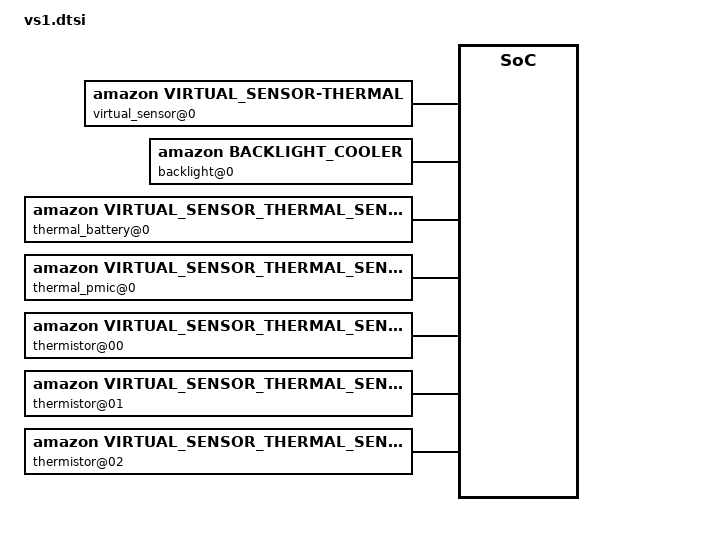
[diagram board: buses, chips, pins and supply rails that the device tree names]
/*
 * Copyright (c) 2017 MediaTek Inc.
 * Author: Keene Tsai <keene.tsai@mediatek.com>
 *
 * This program is free software; you can redistribute it and/or modify
 * it under the terms of the GNU General Public License version 2 as
 * published by the Free Software Foundation.
 *
 * This program is distributed in the hope that it will be useful,
 * MERCHANTABILITY or FITNESS FOR A PARTICULAR PURPOSE.  See the
 * GNU General Public License for more details.
 */
vs1_wire: vs1_wire {
	compatible = "amazon,vs1_wire", "simple-bus";
	status = "okay";

	/*
	 * Virtual sensor
	 * select_device: Decide to register which thermal_zone device
	 * 0: register to thermal_zone9, 1: register to thermal_zone10
	 */
	virtual_sensor@0{
		compatible = "amazon,virtual_sensor-thermal";
		dev_id = <0>;
		num_trips = <9>;
		mode = <0>;
		polling_delay = <3000>;
		governor_name = "virtual_sensor";
		num_tbps = <3>;
		temp = <44000 44500 45000 45500 49000 51000 53000 54000 56000 56000 56000 56000>;
		type = <0 0 0 0 0 0 0 0 3 3 3 3>;
		hyst = <3000 0 0 0 0 0 0 3000 0 0 0 0>;
		num_cdevs = <2>;
		cdev_names = "thermal_budget0","lcd-backlight0";
	};
	/* Backlight Cooler */
	backlight@0 {
		compatible = "amazon,backlight_cooler";
		type = "lcd-backlight0";
		state = <0>;
		max_state = <12>;
		level = <255>;
		thermal_cooler_id = <1>;
		levels = <255 255 255 220 200 175 175 175 175 175 175 175>;
	};

	/* Thermal_budget Cooler */
	thermal_budget@0 {
		compatible = "amazon,thermal_budget_cooler";
		type = "thermal_budget0";
		state = <0>;
		max_state = <12>;
		level = <4600>;
		thermal_cooler_id = <2>;
		levels = <941 846 707 625 553 441 372 235 235 235 235 235>;
	};
	/*Virtual sensor battery*/
	thermal_battery@0{
		compatible = "amazon,virtual_sensor_thermal_sensor";
		thermal_sensor,offset = <5040>;
		thermal_sensor,offset_invert = <0>;
		thermal_sensor,alpha = <726>;
		thermal_sensor,weight = <228>;
		thermal_sensor,weight_invert = <0>;
		thermal_sensor_id = <1>;
		aux_channel_num = <0>;
		select_device = <0>;
	};
	/*Virtual sensor pmic*/
	thermal_pmic@0{
		compatible = "amazon,virtual_sensor_thermal_sensor";
		thermal_sensor,offset = <50200>;
		thermal_sensor,alpha = <417>;
		thermal_sensor,weight = <0>;
		thermal_sensor,weight_invert = <0>;
		thermal_sensor,offset_invert = <0>;
		thermal_sensor_id = <3>;
		aux_channel_num = <0>;
		select_device = <0>;
	};
	/* Virtual sensor thermistor */
	thermistor@00 {
		compatible = "amazon,virtual_sensor_thermal_sensor";
		thermal_sensor,offset = <12600>;
		thermal_sensor,offset_invert = <1>;
		thermal_sensor,alpha = <1>;
		thermal_sensor,weight = <240>;
		thermal_sensor,weight_invert = <0>;
		thermal_sensor_id = <5>;
		aux_channel_num = <0>;
		select_device = <0>;
	};
	thermistor@01 {
		compatible = "amazon,virtual_sensor_thermal_sensor";
		thermal_sensor,offset = <18300>;
		thermal_sensor,offset_invert = <0>;
		thermal_sensor,alpha = <330>;
		thermal_sensor,weight = <160>;
		thermal_sensor,weight_invert = <0>;
		thermal_sensor_id = <5>;
		aux_channel_num = <1>;
		select_device = <0>;
	};
	thermistor@02 {
		compatible = "amazon,virtual_sensor_thermal_sensor";
		thermal_sensor,offset = <16600>;
		thermal_sensor,offset_invert = <1>;
		thermal_sensor,alpha = <232>;
		thermal_sensor,weight = <257>;
		thermal_sensor,weight_invert = <0>;
		thermal_sensor_id = <5>;
		aux_channel_num = <2>;
		select_device = <0>;
	};
};
vs1_wpc: vs1_wpc {
	compatible = "amazon,vs1_wpc", "simple-bus";
	status = "disabled";

	/*
	 * Virtual sensor
	 * select_device: Decide to register which thermal_zone device
	 * 0: register to thermal_zone9, 1: register to thermal_zone10
	 */
	virtual_sensor@0{
		compatible = "amazon,virtual_sensor-thermal";
		dev_id = <0>;
		num_trips = <9>;
		mode = <0>;
		polling_delay = <3000>;
		governor_name = "virtual_sensor";
		num_tbps = <3>;
		temp = <44000 44500 45000 45500 49000 51000 53000 54000 56000 56000 56000 56000>;
		type = <0 0 0 0 0 0 0 0 3 3 3 3>;
		hyst = <3000 0 0 0 0 0 0 3000 0 0 0 0>;
		num_cdevs = <2>;
		cdev_names = "thermal_budget0","lcd-backlight0";
	};
	/* Backlight Cooler */
	backlight@0 {
		compatible = "amazon,backlight_cooler";
		type = "lcd-backlight0";
		state = <0>;
		max_state = <12>;
		level = <255>;
		thermal_cooler_id = <1>;
		levels = <255 255 255 220 200 175 175 175 175 175 175 175>;
	};

	/* Thermal_budget Cooler */
	thermal_budget@0 {
		compatible = "amazon,thermal_budget_cooler";
		type = "thermal_budget0";
		state = <0>;
		max_state = <12>;
		level = <4600>;
		thermal_cooler_id = <2>;
		levels = <941 846 707 625 553 441 372 235 235 235 235 235>;
	};
	/*Virtual sensor battery*/
	thermal_battery@0{
		compatible = "amazon,virtual_sensor_thermal_sensor";
		thermal_sensor,offset = <29700>;
		thermal_sensor,offset_invert = <0>;
		thermal_sensor,alpha = <1000>;
		thermal_sensor,weight = <226>;
		thermal_sensor,weight_invert = <0>;
		thermal_sensor_id = <1>;
		aux_channel_num = <0>;
		select_device = <0>;
	};
	/*Virtual sensor pmic*/
	thermal_pmic@0{
		compatible = "amazon,virtual_sensor_thermal_sensor";
		thermal_sensor,offset = <56200>;
		thermal_sensor,alpha = <1>;
		thermal_sensor,weight = <59>;
		thermal_sensor,weight_invert = <1>;
		thermal_sensor,offset_invert = <0>;
		thermal_sensor_id = <3>;
		aux_channel_num = <0>;
		select_device = <0>;
	};
	/* Virtual sensor thermistor */
	thermistor@00 {
		compatible = "amazon,virtual_sensor_thermal_sensor";
		thermal_sensor,offset = <51000>;
		thermal_sensor,offset_invert = <0>;
		thermal_sensor,alpha = <1>;
		thermal_sensor,weight = <0>;
		thermal_sensor,weight_invert = <0>;
		thermal_sensor_id = <5>;
		aux_channel_num = <0>;
		select_device = <0>;
	};
	thermistor@01 {
		compatible = "amazon,virtual_sensor_thermal_sensor";
		thermal_sensor,offset = <9790>;
		thermal_sensor,offset_invert = <1>;
		thermal_sensor,alpha = <607>;
		thermal_sensor,weight = <718>;
		thermal_sensor,weight_invert = <0>;
		thermal_sensor_id = <5>;
		aux_channel_num = <1>;
		select_device = <0>;
	};
	thermistor@02 {
		compatible = "amazon,virtual_sensor_thermal_sensor";
		thermal_sensor,offset = <53600>;
		thermal_sensor,offset_invert = <0>;
		thermal_sensor,alpha = <147>;
		thermal_sensor,weight = <0>;
		thermal_sensor,weight_invert = <0>;
		thermal_sensor_id = <5>;
		aux_channel_num = <2>;
		select_device = <0>;
	};
};
